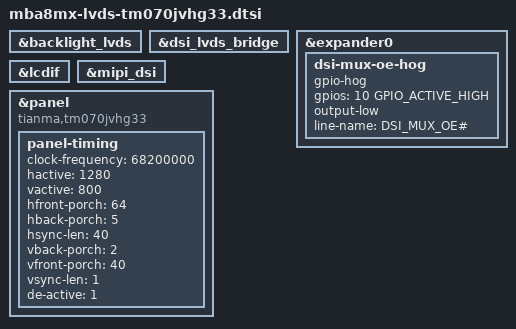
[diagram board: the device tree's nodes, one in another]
// SPDX-License-Identifier: (GPL-2.0-or-later OR MIT)
/*
 * Copyright (c) 2020-2023 TQ-Systems GmbH <linux@ew.tq-group.com>,
 * D-82229 Seefeld, Germany.
 * Author: Alexander Stein
 */

&backlight_lvds {
	status = "okay";
};

&dsi_lvds_bridge {
	status = "okay";
};

&expander0 {
	dsi-mux-oe-hog {
		gpio-hog;
		gpios = <10 GPIO_ACTIVE_HIGH>;
		output-low;
		line-name = "DSI_MUX_OE#";
	};
};

&lcdif {
	status = "okay";
};

&mipi_dsi {
	status = "okay";
};

&panel {
	compatible = "tianma,tm070jvhg33";
	status = "okay";

	panel-timing {
		/*
		 * Override default timings from panel-simple
		 * as i.MX8M requires special timings.
		 */
		clock-frequency = <68200000>;
		hactive = <1280>;
		vactive = <800>;
		hfront-porch = <64>;
		hback-porch = <5>;
		hsync-len = <40>;
		vback-porch = <2>;
		vfront-porch = <40>;
		vsync-len = <1>;

		de-active = <1>;
	};
};
